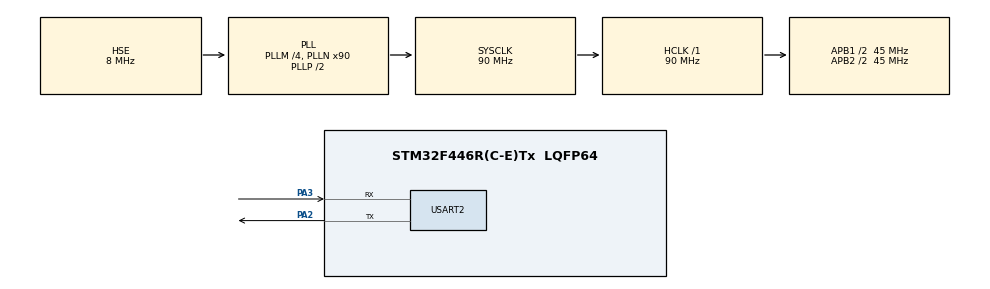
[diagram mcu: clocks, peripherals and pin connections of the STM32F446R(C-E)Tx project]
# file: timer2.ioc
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Dma.Request0=USART2_RX
Dma.Request1=USART2_TX
Dma.USART2_RX.0.Direction=DMA_PERIPH_TO_MEMORY
Dma.USART2_RX.0.FIFOMode=DMA_FIFOMODE_DISABLE
Dma.USART2_RX.0.Instance=DMA1_Stream5
Dma.USART2_RX.0.MemDataAlignment=DMA_MDATAALIGN_BYTE
Dma.USART2_RX.0.MemInc=DMA_MINC_ENABLE
Dma.USART2_RX.0.Mode=DMA_NORMAL
Dma.USART2_RX.0.PeriphDataAlignment=DMA_PDATAALIGN_BYTE
Dma.USART2_RX.0.PeriphInc=DMA_PINC_DISABLE
Dma.USART2_RX.0.Priority=DMA_PRIORITY_LOW
Dma.USART2_TX.1.Direction=DMA_MEMORY_TO_PERIPH
Dma.USART2_TX.1.FIFOMode=DMA_FIFOMODE_DISABLE
Dma.USART2_TX.1.Instance=DMA1_Stream6
Dma.USART2_TX.1.MemDataAlignment=DMA_MDATAALIGN_BYTE
Dma.USART2_TX.1.MemInc=DMA_MINC_ENABLE
Dma.USART2_TX.1.Mode=DMA_NORMAL
Dma.USART2_TX.1.PeriphDataAlignment=DMA_PDATAALIGN_BYTE
Dma.USART2_TX.1.PeriphInc=DMA_PINC_DISABLE
Dma.USART2_TX.1.Priority=DMA_PRIORITY_LOW
Mcu.Family=STM32F4
Mcu.Name=STM32F446R(C-E)Tx
Mcu.Package=LQFP64
NVIC.DMA1_Stream5_IRQn=true\:0\:0\:false\:false\:true\:false\:true\:true
NVIC.DMA1_Stream6_IRQn=true\:0\:0\:false\:false\:true\:false\:true\:true
NVIC.PriorityGroup=NVIC_PRIORITYGROUP_4
NVIC.USART2_IRQn=true\:0\:0\:false\:false\:true\:true\:true\:true
PA2.Mode=Asynchronous
PA2.Signal=USART2_TX
PA3.Mode=Asynchronous
PA3.Signal=USART2_RX
PH0-OSC_IN.Mode=HSE-External-Oscillator
PH0-OSC_IN.Signal=RCC_OSC_IN
PH1-OSC_OUT.Mode=HSE-External-Oscillator
PH1-OSC_OUT.Signal=RCC_OSC_OUT
ProjectManager.HeapSize=0x200
ProjectManager.StackSize=0x400
ProjectManager.TargetToolchain=STM32CubeIDE
RCC.AHBFreq_Value=90000000
RCC.APB1CLKDivider=RCC_HCLK_DIV2
RCC.APB1Freq_Value=45000000
RCC.APB1TimFreq_Value=90000000
RCC.APB2CLKDivider=RCC_HCLK_DIV2
RCC.APB2Freq_Value=45000000
RCC.APB2TimFreq_Value=90000000
RCC.CortexFreq_Value=90000000
RCC.HCLKFreq_Value=90000000
RCC.HSE_VALUE=8000000
RCC.PLLM=4
RCC.PLLN=90
RCC.PLLSourceVirtual=RCC_PLLSOURCE_HSE
RCC.SYSCLKFreq_VALUE=90000000
RCC.SYSCLKSource=RCC_SYSCLKSOURCE_PLLCLK
RCC.USBFreq_Value=90000000
RCC.VCOOutputFreq_Value=180000000
TIM2.Period=9999
TIM2.Prescaler=8999
USART2.VirtualMode=VM_ASYNC
VP_TIM2_VS_ClockSourceINT.Mode=Internal
board=custom

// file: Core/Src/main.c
/* USER CODE BEGIN Header */
/**
  ******************************************************************************
  * @file           : main.c
  * @brief          : Main program body
  ******************************************************************************
  * @attention
  *
  * Copyright (c) 2024 STMicroelectronics.
  * All rights reserved.
  *
  * This software is licensed under terms that can be found in the LICENSE file
  * in the root directory of this software component.
  * If no LICENSE file comes with this software, it is provided AS-IS.
  *
  ******************************************************************************
  */
/* USER CODE END Header */
#include "main.h"

/* USER CODE BEGIN Includes */
#include "stdio.h"
#include "string.h"
/* USER CODE END Includes */

TIM_HandleTypeDef htim2;

UART_HandleTypeDef huart2;
DMA_HandleTypeDef hdma_usart2_rx;
DMA_HandleTypeDef hdma_usart2_tx;

/* USER CODE BEGIN PV */
int counter = 0;	//定義一個整數counter存取計數器的值。定義成全域變數的話可以用現場表達式看值(用uart傳出來看更好)
/* USER CODE END PV */

void SystemClock_Config(void);
static void MX_GPIO_Init(void);
static void MX_DMA_Init(void);
static void MX_TIM2_Init(void);
static void MX_USART2_UART_Init(void);

int main(void)
{

  /* MCU Configuration--------------------------------------------------------*/

  /* Reset of all peripherals, Initializes the Flash interface and the Systick. */
  HAL_Init();

  /* Configure the system clock */
  SystemClock_Config();

  /* Initialize all configured peripherals */
  MX_GPIO_Init();
  MX_DMA_Init();
  MX_TIM2_Init();
  MX_USART2_UART_Init();
  /* USER CODE BEGIN 2 */
  HAL_TIM_Base_Start(&htim2);	//啟用timer的功能(pre-scalar, auto-reload register, counter)
  char message[20];	//定義空字串，用來接要由uart傳出去的字串
  /* USER CODE END 2 */

  /* Infinite loop */
  while (1)
  {

    /* USER CODE BEGIN 3 */
	  counter = __HAL_TIM_GET_COUNTER(&htim2);	//__HAL_TIM_GET_COUNTER是一個偏底層、直接對記憶體動作的宏定義(皆為大寫)，用來取計數器的值。
	  sprintf(message, "counter: %d", counter);	//把取出的值用fprintf塞進空字串message裡面
	  HAL_UART_Transmit_DMA(&huart2, (uint8_t *)message, strlen(message));	//把從計數器取出的值用uart(with DMA或IT都可)傳出來看
	  HAL_Delay(99);	//每隔100毫秒傳一次(設99是因為HAL_Delay的內部設定有點fancy)。如果數10000(0~9999)次 = 1秒 -> 0, 999, 1999, ......, 8999, 9999
  }
  /* USER CODE END 3 */
}

void SystemClock_Config(void)
{
  RCC_OscInitTypeDef RCC_OscInitStruct = {0};
  RCC_ClkInitTypeDef RCC_ClkInitStruct = {0};

  /** Configure the main internal regulator output voltage
  */
  __HAL_RCC_PWR_CLK_ENABLE();
  __HAL_PWR_VOLTAGESCALING_CONFIG(PWR_REGULATOR_VOLTAGE_SCALE3);

  /** Initializes the RCC Oscillators according to the specified parameters
  * in the RCC_OscInitTypeDef structure.
  */
  RCC_OscInitStruct.OscillatorType = RCC_OSCILLATORTYPE_HSE;
  RCC_OscInitStruct.HSEState = RCC_HSE_ON;
  RCC_OscInitStruct.PLL.PLLState = RCC_PLL_ON;
  RCC_OscInitStruct.PLL.PLLSource = RCC_PLLSOURCE_HSE;
  RCC_OscInitStruct.PLL.PLLM = 4;
  RCC_OscInitStruct.PLL.PLLN = 90;
  RCC_OscInitStruct.PLL.PLLP = RCC_PLLP_DIV2;
  RCC_OscInitStruct.PLL.PLLQ = 2;
  RCC_OscInitStruct.PLL.PLLR = 2;
  if (HAL_RCC_OscConfig(&RCC_OscInitStruct) != HAL_OK)
  {
    Error_Handler();
  }

  /** Initializes the CPU, AHB and APB buses clocks
  */
  RCC_ClkInitStruct.ClockType = RCC_CLOCKTYPE_HCLK|RCC_CLOCKTYPE_SYSCLK
                              |RCC_CLOCKTYPE_PCLK1|RCC_CLOCKTYPE_PCLK2;
  RCC_ClkInitStruct.SYSCLKSource = RCC_SYSCLKSOURCE_PLLCLK;
  RCC_ClkInitStruct.AHBCLKDivider = RCC_SYSCLK_DIV1;
  RCC_ClkInitStruct.APB1CLKDivider = RCC_HCLK_DIV2;
  RCC_ClkInitStruct.APB2CLKDivider = RCC_HCLK_DIV2;

  if (HAL_RCC_ClockConfig(&RCC_ClkInitStruct, FLASH_LATENCY_2) != HAL_OK)
  {
    Error_Handler();
  }
}

static void MX_TIM2_Init(void)
{

  TIM_ClockConfigTypeDef sClockSourceConfig = {0};
  TIM_MasterConfigTypeDef sMasterConfig = {0};

  htim2.Instance = TIM2;
  htim2.Init.Prescaler = 8999;
  htim2.Init.CounterMode = TIM_COUNTERMODE_UP;
  htim2.Init.Period = 9999;
  htim2.Init.ClockDivision = TIM_CLOCKDIVISION_DIV1;
  htim2.Init.AutoReloadPreload = TIM_AUTORELOAD_PRELOAD_DISABLE;
  if (HAL_TIM_Base_Init(&htim2) != HAL_OK)
  {
    Error_Handler();
  }
  sClockSourceConfig.ClockSource = TIM_CLOCKSOURCE_INTERNAL;
  if (HAL_TIM_ConfigClockSource(&htim2, &sClockSourceConfig) != HAL_OK)
  {
    Error_Handler();
  }
  sMasterConfig.MasterOutputTrigger = TIM_TRGO_RESET;
  sMasterConfig.MasterSlaveMode = TIM_MASTERSLAVEMODE_DISABLE;
  if (HAL_TIMEx_MasterConfigSynchronization(&htim2, &sMasterConfig) != HAL_OK)
  {
    Error_Handler();
  }

}

static void MX_USART2_UART_Init(void)
{

  huart2.Instance = USART2;
  huart2.Init.BaudRate = 115200;
  huart2.Init.WordLength = UART_WORDLENGTH_8B;
  huart2.Init.StopBits = UART_STOPBITS_1;
  huart2.Init.Parity = UART_PARITY_NONE;
  huart2.Init.Mode = UART_MODE_TX_RX;
  huart2.Init.HwFlowCtl = UART_HWCONTROL_NONE;
  huart2.Init.OverSampling = UART_OVERSAMPLING_16;
  if (HAL_UART_Init(&huart2) != HAL_OK)
  {
    Error_Handler();
  }

}

static void MX_DMA_Init(void)
{

  /* DMA controller clock enable */
  __HAL_RCC_DMA1_CLK_ENABLE();

  /* DMA interrupt init */
  /* DMA1_Stream5_IRQn interrupt configuration */
  HAL_NVIC_SetPriority(DMA1_Stream5_IRQn, 0, 0);
  HAL_NVIC_EnableIRQ(DMA1_Stream5_IRQn);
  /* DMA1_Stream6_IRQn interrupt configuration */
  HAL_NVIC_SetPriority(DMA1_Stream6_IRQn, 0, 0);
  HAL_NVIC_EnableIRQ(DMA1_Stream6_IRQn);

}

static void MX_GPIO_Init(void)
{

  /* GPIO Ports Clock Enable */
  __HAL_RCC_GPIOH_CLK_ENABLE();
  __HAL_RCC_GPIOA_CLK_ENABLE();

}

void Error_Handler(void)
{
  __disable_irq();
  while (1)
  {
  }
}
